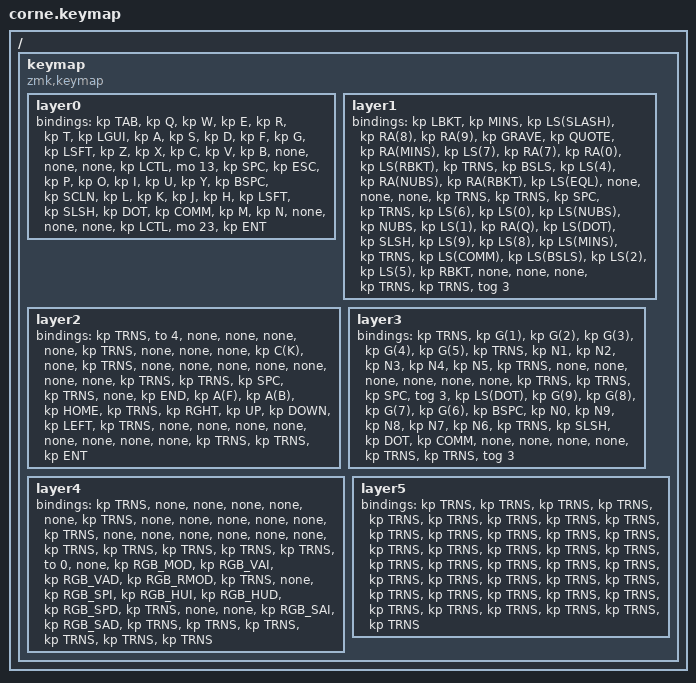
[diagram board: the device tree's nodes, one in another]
/ {
    keymap {
        compatible = "zmk,keymap";

        // Layer 0
        layer0 {
            bindings = <
                &kp TAB  &kp Q  &kp W  &kp E  &kp R  &kp T     &kp LGUI
                &kp A    &kp S  &kp D  &kp F  &kp G               &kp LSFT
                &kp Z    &kp X  &kp C  &kp V  &kp B               &none  &none  &none  &kp LCTL  &mo 13  &kp SPC
                &kp ESC  &kp P  &kp O  &kp I  &kp U  &kp Y       &kp BSPC
                &kp SCLN &kp L  &kp K  &kp J  &kp H               &kp LSFT
                &kp SLSH &kp DOT &kp COMM &kp M &kp N            &none  &none  &none  &kp LCTL  &mo 23  &kp ENT
            >;
        };

        // Layer 1
        layer1 {
            bindings = <
                &kp LBKT   &kp MINS  &kp LS(SLASH)  &kp RA(8)  &kp RA(9)  &kp GRAVE
                &kp QUOTE  &kp RA(MINS)  &kp LS(7)  &kp RA(7)  &kp RA(0)  &kp LS(RBKT)
                &kp TRNS   &kp BSLS  &kp LS(4)  &kp RA(NUBS)  &kp RA(RBKT)  &kp LS(EQL)
                &none      &none     &none       &kp TRNS  &kp TRNS  &kp SPC
                &kp TRNS   &kp LS(6) &kp LS(0)  &kp LS(NUBS)  &kp NUBS   &kp LS(1)
                &kp RA(Q)  &kp LS(DOT)  &kp SLSH &kp LS(9)  &kp LS(8)  &kp LS(MINS)
                &kp TRNS   &kp LS(COMM)  &kp LS(BSLS)  &kp LS(2)  &kp LS(5)
                &kp RBKT   &none      &none      &none      &kp TRNS  &kp TRNS  &tog 3
            >;
        };

        // Layer 2
        layer2 {
            bindings = <
                &kp TRNS   &to 4   &none     &none     &none     &none   &kp TRNS
                &none      &none   &none     &kp C(K)  &none     &kp TRNS
                &none      &none   &none     &none     &none     &none
                &none      &kp TRNS  &kp TRNS  &kp SPC  &kp TRNS  &none
                &kp END    &kp A(F)  &kp A(B)  &kp HOME  &kp TRNS &kp RGHT
                &kp UP     &kp DOWN  &kp LEFT  &kp TRNS  &none    &none
                &none      &none     &none     &none     &none    &none
                &kp TRNS   &kp TRNS  &kp ENT
            >;
        };

        // Layer 3
        layer3 {
            bindings = <
                &kp TRNS   &kp G(1)  &kp G(2)  &kp G(3)  &kp G(4)  &kp G(5)
                &kp TRNS   &kp N1    &kp N2    &kp N3    &kp N4    &kp N5
                &kp TRNS   &none     &none     &none     &none     &none
                &none      &kp TRNS  &kp TRNS  &kp SPC   &tog 3    &kp LS(DOT)
                &kp G(9)   &kp G(8)  &kp G(7)  &kp G(6)  &kp BSPC  &kp N0
                &kp N9     &kp N8    &kp N7    &kp N6    &kp TRNS  &kp SLSH
                &kp DOT    &kp COMM  &none     &none     &none     &none
                &kp TRNS   &kp TRNS  &tog 3
            >;
        };

        // Layer 4
        layer4 {
            bindings = <
                &kp TRNS   &none    &none     &none    &none    &none
                &kp TRNS   &none    &none     &none    &none    &none
                &kp TRNS   &none    &none     &none    &none    &none
                &none      &kp TRNS &kp TRNS  &kp TRNS &kp TRNS &kp TRNS
                &to 0      &none    &kp RGB_MOD &kp RGB_VAI &kp RGB_VAD &kp RGB_RMOD
                &kp TRNS   &none    &kp RGB_SPI &kp RGB_HUI &kp RGB_HUD &kp RGB_SPD
                &kp TRNS   &none    &none      &kp RGB_SAI &kp RGB_SAD
                &kp TRNS   &kp TRNS &kp TRNS   &kp TRNS &kp TRNS &kp TRNS
            >;
        };

        // Layer 5 (Empty Layer)
        layer5 {
            bindings = <
                &kp TRNS &kp TRNS &kp TRNS &kp TRNS &kp TRNS
                &kp TRNS &kp TRNS &kp TRNS &kp TRNS &kp TRNS
                &kp TRNS &kp TRNS &kp TRNS &kp TRNS &kp TRNS
                &kp TRNS &kp TRNS &kp TRNS &kp TRNS &kp TRNS
                &kp TRNS &kp TRNS &kp TRNS &kp TRNS &kp TRNS
                &kp TRNS &kp TRNS &kp TRNS &kp TRNS &kp TRNS
                &kp TRNS &kp TRNS &kp TRNS &kp TRNS &kp TRNS
                &kp TRNS &kp TRNS &kp TRNS &kp TRNS &kp TRNS
            >;
        };
    };
};
